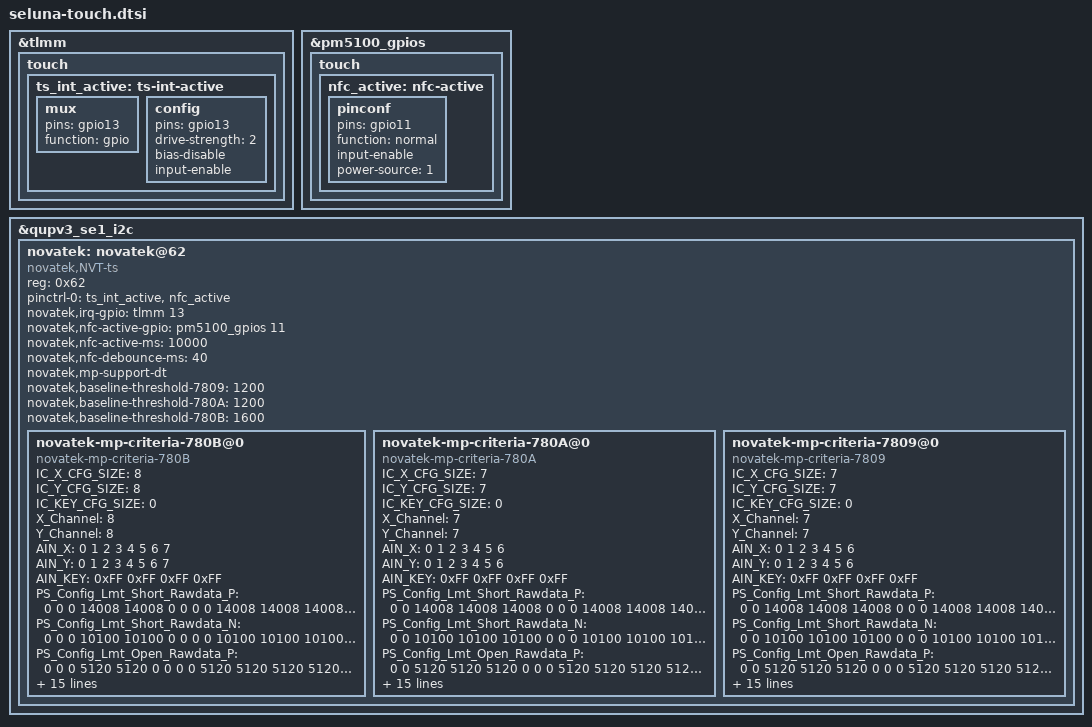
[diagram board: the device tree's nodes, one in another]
// SPDX-License-Identifier: GPL-2.0

#include <dt-bindings/gpio/gpio.h>

&tlmm {
	touch {
		ts_int_active: ts-int-active {
			mux {
				pins = "gpio13";
				function = "gpio";
			};

			config {
				pins = "gpio13";
				drive-strength = <2>;
				bias-disable;
				input-enable;
			};
		};
	};
};

&pm5100_gpios {
	touch {
		nfc_active: nfc-active {
			pinconf {
				pins = "gpio11";
				function = "normal";
				input-enable;
				power-source = <1>;
			};
		};
	};
};

&qupv3_se1_i2c {
	#address-cells = <1>;
	#size-cells = <0>;

	status = "okay";

	novatek: novatek@62 {
		compatible = "novatek,NVT-ts";
		reg = <0x62>;
		status = "okay";

		pinctrl-names = "default";

		pinctrl-0 = <&ts_int_active &nfc_active>;

		novatek,irq-gpio = <&tlmm 13 GPIO_ACTIVE_HIGH>;
		novatek,nfc-active-gpio = <&pm5100_gpios 11 GPIO_ACTIVE_HIGH>;
		novatek,nfc-active-ms = <10000>;
		novatek,nfc-debounce-ms = <40>;

		novatek,mp-support-dt;

		novatek,baseline-threshold-7809 = /bits/ 16 <1200>;  // Selene BOE
		novatek,baseline-threshold-780A = /bits/ 16 <1200>;  // Selene SDC
		novatek,baseline-threshold-780B = /bits/ 16 <1600>;  // Luna BOE
	};
};


&novatek {
	// Luna - BOE
	novatek-mp-criteria-780B@0 {
		#address-cells = <1>;
		#size-cells = <0>;
		compatible = "novatek-mp-criteria-780B";

		/* MP Config */
		IC_X_CFG_SIZE = <8>;
		IC_Y_CFG_SIZE = <8>;
		IC_KEY_CFG_SIZE = <0>;
		X_Channel = <8>;
		Y_Channel = <8>;
		AIN_X = <0 1 2 3 4 5 6 7>;
		AIN_Y = <0 1 2 3 4 5 6 7>;
		AIN_KEY = <0xFF 0xFF 0xFF 0xFF>;

		/* MP Criteria */
		PS_Config_Lmt_Short_Rawdata_P = <
			0 0 0 14008 14008 0 0 0
			0 14008 14008 14008 14008 14008 14008 0
			0 14008 14008 14008 14008 14008 14008 0
			14008 14008 14008 14008 14008 14008 14008 14008
			14008 14008 14008 14008 14008 14008 14008 14008
			0 14008 14008 14008 14008 14008 14008 0
			0 14008 14008 14008 14008 14008 14008 0
			0 0 0 14008 14008 0 0 0
			14008 14008 14008>;

		PS_Config_Lmt_Short_Rawdata_N = <
			0 0 0 10100 10100 0 0 0
			0 10100 10100 10100 10100 10100 10100 0
			0 10100 10100 10100 10100 10100 10100 0
			10100 10100 10100 10100 10100 10100 10100 10100
			10100 10100 10100 10100 10100 10100 10100 10100
			0 10100 10100 10100 10100 10100 10100 0
			0 10100 10100 10100 10100 10100 10100 0
			0 0 0 10100 10100 0 0 0
			10100 10100 10100>;

		PS_Config_Lmt_Open_Rawdata_P = <
			0 0 0 5120 5120 0 0 0
			0 5120 5120 5120 5120 5120 5120 0
			0 5120 5120 5120 5120 5120 5120 0
			5120 5120 5120 5120 5120 5120 5120 5120
			5120 5120 5120 5120 5120 5120 5120 5120
			0 5120 5120 5120 5120 5120 5120 0
			0 5120 5120 5120 5120 5120 5120 0
			0 0 0 5120 5120 0 0 0
			5120 5120 5120>;

		PS_Config_Lmt_Open_Rawdata_N = <
			0 0 0 1000 1000 0 0 0
			0 1000 1000 1000 1000 1000 1000 0
			0 1000 1000 1000 1000 1000 1000 0
			1000 1000 1000 1000 1000 1000 1000 1000
			1000 1000 1000 1000 1000 1000 1000 1000
			0 1000 1000 1000 1000 1000 1000 0
			0 1000 1000 1000 1000 1000 1000 0
			0 0 0 1000 1000 0 0 0
			1000 1000 1000>;

		PS_Config_Lmt_FW_Rawdata_P = <
			0 0 0 10000 10000 0 0 0
			0 10000 10000 10000 10000 10000 10000 0
			0 10000 10000 10000 10000 10000 10000 0
			10000 10000 10000 10000 10000 10000 10000 10000
			10000 10000 10000 10000 10000 10000 10000 10000
			0 10000 10000 10000 10000 10000 10000 0
			0 10000 10000 10000 10000 10000 10000 0
			0 0 0 10000 10000 0 0 0
			10000 10000 10000>;

		PS_Config_Lmt_FW_Rawdata_N = <
			0 0 0 0 0 0 0 0
			0 0 0 0 0 0 0 0
			0 0 0 0 0 0 0 0
			0 0 0 0 0 0 0 0
			0 0 0 0 0 0 0 0
			0 0 0 0 0 0 0 0
			0 0 0 0 0 0 0 0
			0 0 0 0 0 0 0 0
			0 0 0>;

		PS_Config_Lmt_FW_CC_P = <
			0 0 0 65535 65535 0 0 0
			0 65535 65535 65535 65535 65535 65535 0
			0 65535 65535 65535 65535 65535 65535 0
			65535 65535 65535 65535 65535 65535 65535 65535
			65535 65535 65535 65535 65535 65535 65535 65535
			0 65535 65535 65535 65535 65535 65535 0
			0 65535 65535 65535 65535 65535 65535 0
			0 0 0 65535 65535 0 0 0
			65535 65535 65535>;

		PS_Config_Lmt_FW_CC_N = <
			0 0 0 (-65535) (-65535) 0 0 0
			0 (-65535) (-65535) (-65535) (-65535) (-65535) (-65535) 0
			0 (-65535) (-65535) (-65535) (-65535) (-65535) (-65535) 0
			(-65535) (-65535) (-65535) (-65535) (-65535) (-65535) (-65535) (-65535)
			(-65535) (-65535) (-65535) (-65535) (-65535) (-65535) (-65535) (-65535)
			0 (-65535) (-65535) (-65535) (-65535) (-65535) (-65535) 0
			0 (-65535) (-65535) (-65535) (-65535) (-65535) (-65535) 0
			0 0 0 (-65535) (-65535) 0 0 0
			0 0 0>;

		PS_Config_Lmt_FW_Diff_P = <
			0 0 0 75 75 0 0 0
			0 75 75 75 75 75 75 0
			0 75 75 75 75 75 75 0
			75 75 75 75 75 75 75 75
			75 75 75 75 75 75 75 75
			0 75 75 75 75 75 75 0
			0 75 75 75 75 75 75 0
			0 0 0 75 75 0 0 0
			75 75 75>;

		PS_Config_Lmt_FW_Diff_N = <
			0 0 0 (-75) (-75) 0 0 0
			0 (-75) (-75) (-75) (-75) (-75) (-75) 0
			0 (-75) (-75) (-75) (-75) (-75) (-75) 0
			(-75) (-75) (-75) (-75) (-75) (-75) (-75) (-75)
			(-75) (-75) (-75) (-75) (-75) (-75) (-75) (-75)
			0 (-75) (-75) (-75) (-75) (-75) (-75) 0
			0 (-75) (-75) (-75) (-75) (-75) (-75) 0
			0 0 0 (-75) (-75) 0 0 0
			(-75) (-75) (-75)>;

		PS_Config_Diff_Test_Frame = <50>;
	};
	// Selene - SDC
	novatek-mp-criteria-780A@0 {
		#address-cells = <1>;
		#size-cells = <0>;
		compatible = "novatek-mp-criteria-780A";

		/* MP Config */
		IC_X_CFG_SIZE = <7>;
		IC_Y_CFG_SIZE = <7>;
		IC_KEY_CFG_SIZE = <0>;
		X_Channel = <7>;
		Y_Channel = <7>;
		AIN_X = <0 1 2 3 4 5 6>;
		AIN_Y = <0 1 2 3 4 5 6>;
		AIN_KEY = <0xFF 0xFF 0xFF 0xFF>;

		/* MP Criteria */
		PS_Config_Lmt_Short_Rawdata_P = <
			0 0 14008 14008 14008 0 0
			0 14008 14008 14008 14008 14008 0
			14008 14008 14008 14008 14008 14008 14008
			14008 14008 14008 14008 14008 14008 14008
			14008 14008 14008 14008 14008 14008 14008
			0 14008 14008 14008 14008 14008 0
			0 0 14008 14008 14008 0 0
			14008 14008 14008>;

		PS_Config_Lmt_Short_Rawdata_N = <
			0 0 10100 10100 10100 0 0
			0 10100 10100 10100 10100 10100 0
			10100 10100 10100 10100 10100 10100 10100
			10100 10100 10100 10100 10100 10100 10100
			10100 10100 10100 10100 10100 10100 10100
			0 10100 10100 10100 10100 10100 0
			0 0 10100 10100 10100 0 0
			10100 10100 10100>;

		PS_Config_Lmt_Open_Rawdata_P = <
			0 0 5120 5120 5120 0 0
			0 5120 5120 5120 5120 5120 0
			5120 5120 5120 5120 5120 5120 5120
			5120 5120 5120 5120 5120 5120 5120
			5120 5120 5120 5120 5120 5120 5120
			0 5120 5120 5120 5120 5120 0
			0 0 5120 5120 5120 0 0
			5120 5120 5120>;

		PS_Config_Lmt_Open_Rawdata_N = <
			0 0 1000 1000 1000 0 0
			0 1000 1000 1000 1000 1000 0
			1000 1000 1000 1000 1000 1000 1000
			1000 1000 1000 1000 1000 1000 1000
			1000 1000 1000 1000 1000 1000 1000
			0 1000 1000 1000 1000 1000 0
			0 0 1000 1000 1000 0 0
			1000 1000 1000>;

		PS_Config_Lmt_FW_Rawdata_P = <
			0 0 10000 10000 10000 0 0
			0 10000 10000 10000 10000 10000 0
			10000 10000 10000 10000 10000 10000 10000
			10000 10000 10000 10000 10000 10000 10000
			10000 10000 10000 10000 10000 10000 10000
			0 10000 10000 10000 10000 10000 0
			0 0 10000 10000 10000 0 0
			10000 10000 10000>;

		PS_Config_Lmt_FW_Rawdata_N = <
			0 0 0 0 0 0 0
			0 0 0 0 0 0 0
			0 0 0 0 0 0 0
			0 0 0 0 0 0 0
			0 0 0 0 0 0 0
			0 0 0 0 0 0 0
			0 0 0 0 0 0 0
			0 0 0>;

		PS_Config_Lmt_FW_CC_P = <
			0 0 65535 65535 65535 0 0
			0 65535 65535 65535 65535 65535 0
			65535 65535 65535 65535 65535 65535 65535
			65535 65535 65535 65535 65535 65535 65535
			65535 65535 65535 65535 65535 65535 65535
			0 65535 65535 65535 65535 65535 0
			0 0 65535 65535 65535 0 0
			65535 65535 65535>;

		PS_Config_Lmt_FW_CC_N = <
			0 0 (-65535) (-65535) (-65535) 0 0
			0 (-65535) (-65535) (-65535) (-65535) (-65535) 0
			(-65535) (-65535) (-65535) (-65535) (-65535) (-65535) (-65535)
			(-65535) (-65535) (-65535) (-65535) (-65535) (-65535) (-65535)
			(-65535) (-65535) (-65535) (-65535) (-65535) (-65535) (-65535)
			0 (-65535) (-65535) (-65535) (-65535) (-65535) 0
			0 0 (-65535) (-65535) (-65535) (-65535) 0
			0 0 0>;

		PS_Config_Lmt_FW_Diff_P = <
			0 0 75 75 75 0 0
			0 75 75 75 75 75 0
			75 75 75 75 75 75 75
			75 75 75 75 75 75 75
			75 75 75 75 75 75 75
			0 75 75 75 75 75 0
			0 0 75 75 75 0 0
			75 75 75>;

		PS_Config_Lmt_FW_Diff_N = <
			0 0 (-75) (-75) (-75) 0 0
			0 (-75) (-75) (-75) (-75) (-75) 0
			(-75) (-75) (-75) (-75) (-75) (-75) (-75)
			(-75) (-75) (-75) (-75) (-75) (-75) (-75)
			(-75) (-75) (-75) (-75) (-75) (-75) (-75)
			0 (-75) (-75) (-75) (-75) (-75) 0
			0 0 (-75) (-75) (-75) 0 0
			(-75) (-75) (-75)>;

		PS_Config_Diff_Test_Frame = <50>;
	};
	// Selene - BOE
	novatek-mp-criteria-7809@0 {
		#address-cells = <1>;
		#size-cells = <0>;
		compatible = "novatek-mp-criteria-7809";

		/* MP Config */
		IC_X_CFG_SIZE = <7>;
		IC_Y_CFG_SIZE = <7>;
		IC_KEY_CFG_SIZE = <0>;
		X_Channel = <7>;
		Y_Channel = <7>;
		AIN_X = <0 1 2 3 4 5 6>;
		AIN_Y = <0 1 2 3 4 5 6>;
		AIN_KEY = <0xFF 0xFF 0xFF 0xFF>;

		/* MP Criteria */
		PS_Config_Lmt_Short_Rawdata_P = <
			0 0 14008 14008 14008 0 0
			0 14008 14008 14008 14008 14008 0
			14008 14008 14008 14008 14008 14008 14008
			14008 14008 14008 14008 14008 14008 14008
			14008 14008 14008 14008 14008 14008 14008
			0 14008 14008 14008 14008 14008 0
			0 0 14008 14008 14008 0 0
			14008 14008 14008>;

		PS_Config_Lmt_Short_Rawdata_N = <
			0 0 10100 10100 10100 0 0
			0 10100 10100 10100 10100 10100 0
			10100 10100 10100 10100 10100 10100 10100
			10100 10100 10100 10100 10100 10100 10100
			10100 10100 10100 10100 10100 10100 10100
			0 10100 10100 10100 10100 10100 0
			0 0 10100 10100 10100 0 0
			10100 10100 10100>;

		PS_Config_Lmt_Open_Rawdata_P = <
			0 0 5120 5120 5120 0 0
			0 5120 5120 5120 5120 5120 0
			5120 5120 5120 5120 5120 5120 5120
			5120 5120 5120 5120 5120 5120 5120
			5120 5120 5120 5120 5120 5120 5120
			0 5120 5120 5120 5120 5120 0
			0 0 5120 5120 5120 0 0
			5120 5120 5120>;

		PS_Config_Lmt_Open_Rawdata_N = <
			0 0 1000 1000 1000 0 0
			0 1000 1000 1000 1000 1000 0
			1000 1000 1000 1000 1000 1000 1000
			1000 1000 1000 1000 1000 1000 1000
			1000 1000 1000 1000 1000 1000 1000
			0 1000 1000 1000 1000 1000 0
			0 0 1000 1000 1000 0 0
			1000 1000 1000>;

		PS_Config_Lmt_FW_Rawdata_P = <
			0 0 10000 10000 10000 0 0
			0 10000 10000 10000 10000 10000 0
			10000 10000 10000 10000 10000 10000 10000
			10000 10000 10000 10000 10000 10000 10000
			10000 10000 10000 10000 10000 10000 10000
			0 10000 10000 10000 10000 10000 0
			0 0 10000 10000 10000 0 0
			10000 10000 10000>;

		PS_Config_Lmt_FW_Rawdata_N = <
			0 0 0 0 0 0 0
			0 0 0 0 0 0 0
			0 0 0 0 0 0 0
			0 0 0 0 0 0 0
			0 0 0 0 0 0 0
			0 0 0 0 0 0 0
			0 0 0 0 0 0 0
			0 0 0>;

		PS_Config_Lmt_FW_CC_P = <
			0 0 65535 65535 65535 0 0
			0 65535 65535 65535 65535 65535 0
			65535 65535 65535 65535 65535 65535 65535
			65535 65535 65535 65535 65535 65535 65535
			65535 65535 65535 65535 65535 65535 65535
			0 65535 65535 65535 65535 65535 0
			0 0 65535 65535 65535 0 0
			65535 65535 65535>;

		PS_Config_Lmt_FW_CC_N = <
			0 0 (-65535) (-65535) (-65535) 0 0
			0 (-65535) (-65535) (-65535) (-65535) (-65535) 0
			(-65535) (-65535) (-65535) (-65535) (-65535) (-65535) (-65535)
			(-65535) (-65535) (-65535) (-65535) (-65535) (-65535) (-65535)
			(-65535) (-65535) (-65535) (-65535) (-65535) (-65535) (-65535)
			0 (-65535) (-65535) (-65535) (-65535) (-65535) 0
			0 0 (-65535) (-65535) (-65535) (-65535) 0
			0 0 0>;

		PS_Config_Lmt_FW_Diff_P = <
			0 0 75 75 75 0 0
			0 75 75 75 75 75 0
			75 75 75 75 75 75 75
			75 75 75 75 75 75 75
			75 75 75 75 75 75 75
			0 75 75 75 75 75 0
			0 0 75 75 75 0 0
			75 75 75>;

		PS_Config_Lmt_FW_Diff_N = <
			0 0 (-75) (-75) (-75) 0 0
			0 (-75) (-75) (-75) (-75) (-75) 0
			(-75) (-75) (-75) (-75) (-75) (-75) (-75)
			(-75) (-75) (-75) (-75) (-75) (-75) (-75)
			(-75) (-75) (-75) (-75) (-75) (-75) (-75)
			0 (-75) (-75) (-75) (-75) (-75) 0
			0 0 (-75) (-75) (-75) 0 0
			(-75) (-75) (-75)>;

		PS_Config_Diff_Test_Frame = <50>;
	};
};
